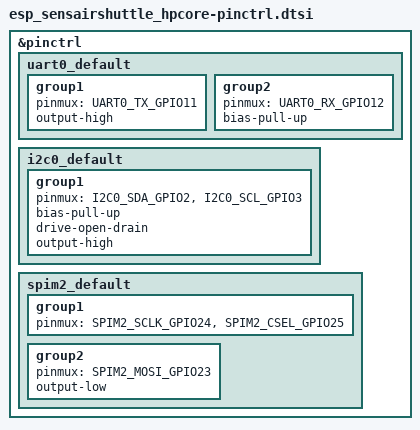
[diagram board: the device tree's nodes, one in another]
/*
 * Copyright (c) 2026 Espressif Systems (Shanghai) Co., Ltd.
 *
 * SPDX-License-Identifier: Apache-2.0
 */

#include <zephyr/dt-bindings/pinctrl/esp32c5-pinctrl.h>

&pinctrl {
	uart0_default: uart0_default {
		group1 {
			pinmux = <UART0_TX_GPIO11>;
			output-high;
		};

		group2 {
			pinmux = <UART0_RX_GPIO12>;
			bias-pull-up;
		};
	};

	i2c0_default: i2c0_default {
		group1 {
			pinmux = <I2C0_SDA_GPIO2>,
				 <I2C0_SCL_GPIO3>;
			bias-pull-up;
			drive-open-drain;
			output-high;
		};
	};

	spim2_default: spim2_default {
		group1 {
			pinmux = <SPIM2_SCLK_GPIO24>,
				 <SPIM2_CSEL_GPIO25>;
		};

		group2 {
			pinmux = <SPIM2_MOSI_GPIO23>;
			output-low;
		};
	};
};
